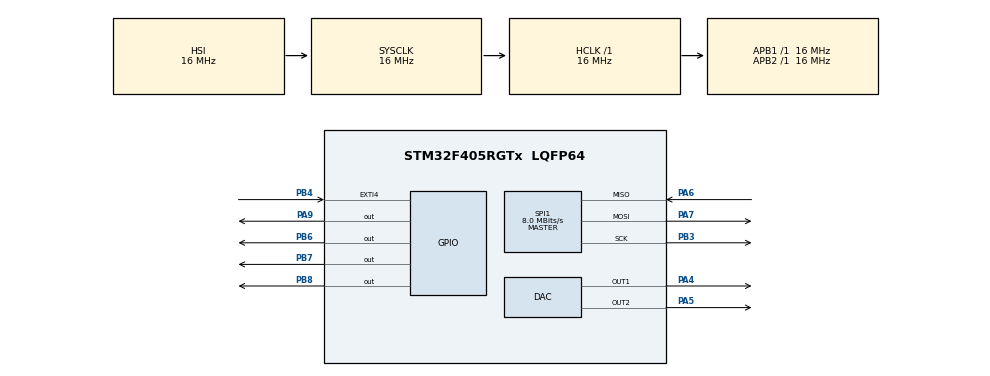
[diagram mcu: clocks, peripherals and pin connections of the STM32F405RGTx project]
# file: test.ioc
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Dma.Request0=SPI1_TX
Dma.SPI1_TX.0.Direction=DMA_MEMORY_TO_PERIPH
Dma.SPI1_TX.0.FIFOMode=DMA_FIFOMODE_DISABLE
Dma.SPI1_TX.0.Instance=DMA2_Stream3
Dma.SPI1_TX.0.MemDataAlignment=DMA_MDATAALIGN_BYTE
Dma.SPI1_TX.0.MemInc=DMA_MINC_ENABLE
Dma.SPI1_TX.0.Mode=DMA_NORMAL
Dma.SPI1_TX.0.PeriphDataAlignment=DMA_PDATAALIGN_BYTE
Dma.SPI1_TX.0.PeriphInc=DMA_PINC_DISABLE
Dma.SPI1_TX.0.Priority=DMA_PRIORITY_LOW
Mcu.Family=STM32F4
Mcu.Name=STM32F405RGTx
Mcu.Package=LQFP64
NVIC.DMA2_Stream3_IRQn=true\:0\:0\:false\:false\:true\:false\:true\:true
NVIC.EXTI4_IRQn=true\:0\:0\:false\:false\:true\:true\:true\:true
NVIC.PriorityGroup=NVIC_PRIORITYGROUP_4
PA13.Mode=Serial_Wire
PA13.Signal=SYS_JTMS-SWDIO
PA14.Mode=Serial_Wire
PA14.Signal=SYS_JTCK-SWCLK
PA4.Signal=COMP_DAC1_group
PA5.Signal=COMP_DAC2_group
PA6.GPIO_PuPd=GPIO_PULLUP
PA6.Mode=Full_Duplex_Master
PA6.Signal=SPI1_MISO
PA7.GPIO_PuPd=GPIO_PULLUP
PA7.Mode=Full_Duplex_Master
PA7.Signal=SPI1_MOSI
PA9.Signal=GPIO_Output
PB3.GPIO_PuPd=GPIO_PULLUP
PB3.Mode=Full_Duplex_Master
PB3.Signal=SPI1_SCK
PB4.Signal=GPXTI4
PB6.PinState=GPIO_PIN_SET
PB6.Signal=GPIO_Output
PB7.Signal=GPIO_Output
PB8.Signal=GPIO_Output
PH0-OSC_IN.Mode=HSE-External-Oscillator
PH0-OSC_IN.Signal=RCC_OSC_IN
PH1-OSC_OUT.Mode=HSE-External-Oscillator
PH1-OSC_OUT.Signal=RCC_OSC_OUT
ProjectManager.HeapSize=0x200
ProjectManager.StackSize=0x400
ProjectManager.TargetToolchain=STM32CubeIDE
RCC.AHBFreq_Value=16000000
RCC.APB1Freq_Value=16000000
RCC.APB2Freq_Value=16000000
RCC.CortexFreq_Value=16000000
RCC.HSE_VALUE=25000000
RCC.HSI_VALUE=16000000
RCC.LSE_VALUE=32768
RCC.SYSCLKFreq_VALUE=16000000
RCC.VCOOutputFreq_Value=192000000
SH.COMP_DAC1_group.0=DAC_OUT1,DAC_OUT1
SH.COMP_DAC2_group.0=DAC_OUT2,DAC_OUT2
SPI1.CalculateBaudRate=8.0 MBits/s
SPI1.Direction=SPI_DIRECTION_2LINES
SPI1.Mode=SPI_MODE_MASTER
SPI1.VirtualType=VM_MASTER
board=custom

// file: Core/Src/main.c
/* USER CODE BEGIN Header */
/**
  ******************************************************************************
  * @file           : main.c
  * @brief          : Main program body
  ******************************************************************************
  * @attention
  *
  * Copyright (c) 2024 STMicroelectronics.
  * All rights reserved.
  *
  * This software is licensed under terms that can be found in the LICENSE file
  * in the root directory of this software component.
  * If no LICENSE file comes with this software, it is provided AS-IS.
  *
  ******************************************************************************
  */
/* USER CODE END Header */
#include "main.h"

/* USER CODE BEGIN Includes */
#include "st7789.h"
/* USER CODE END Includes */

DAC_HandleTypeDef hdac;

SPI_HandleTypeDef hspi1;
DMA_HandleTypeDef hdma_spi1_tx;

void SystemClock_Config(void);
static void MX_GPIO_Init(void);
static void MX_DMA_Init(void);
static void MX_DAC_Init(void);
static void MX_SPI1_Init(void);

int main(void)
{

  /* MCU Configuration--------------------------------------------------------*/

  /* Reset of all peripherals, Initializes the Flash interface and the Systick. */
  HAL_Init();

  /* Configure the system clock */
  SystemClock_Config();

  /* Initialize all configured peripherals */
  MX_GPIO_Init();
  MX_DMA_Init();
  MX_DAC_Init();
  MX_SPI1_Init();
  /* USER CODE BEGIN 2 */
  ST7789_Init();
//  ST7789_Test();
  ST7789_WriteString(10, 10, "Hello Nguyen Dang Tri", Font_7x10, RED, BLACK);
  /* USER CODE END 2 */

  /* Infinite loop */
  while (1)
  {

  }
}

void SystemClock_Config(void)
{
  RCC_OscInitTypeDef RCC_OscInitStruct = {0};
  RCC_ClkInitTypeDef RCC_ClkInitStruct = {0};

  /** Configure the main internal regulator output voltage
  */
  __HAL_RCC_PWR_CLK_ENABLE();
  __HAL_PWR_VOLTAGESCALING_CONFIG(PWR_REGULATOR_VOLTAGE_SCALE1);

  /** Initializes the RCC Oscillators according to the specified parameters
  * in the RCC_OscInitTypeDef structure.
  */
  RCC_OscInitStruct.OscillatorType = RCC_OSCILLATORTYPE_HSI;
  RCC_OscInitStruct.HSIState = RCC_HSI_ON;
  RCC_OscInitStruct.HSICalibrationValue = RCC_HSICALIBRATION_DEFAULT;
  RCC_OscInitStruct.PLL.PLLState = RCC_PLL_NONE;
  if (HAL_RCC_OscConfig(&RCC_OscInitStruct) != HAL_OK)
  {
    Error_Handler();
  }

  /** Initializes the CPU, AHB and APB buses clocks
  */
  RCC_ClkInitStruct.ClockType = RCC_CLOCKTYPE_HCLK|RCC_CLOCKTYPE_SYSCLK
                              |RCC_CLOCKTYPE_PCLK1|RCC_CLOCKTYPE_PCLK2;
  RCC_ClkInitStruct.SYSCLKSource = RCC_SYSCLKSOURCE_HSI;
  RCC_ClkInitStruct.AHBCLKDivider = RCC_SYSCLK_DIV1;
  RCC_ClkInitStruct.APB1CLKDivider = RCC_HCLK_DIV1;
  RCC_ClkInitStruct.APB2CLKDivider = RCC_HCLK_DIV1;

  if (HAL_RCC_ClockConfig(&RCC_ClkInitStruct, FLASH_LATENCY_0) != HAL_OK)
  {
    Error_Handler();
  }
}

static void MX_DAC_Init(void)
{

  DAC_ChannelConfTypeDef sConfig = {0};

  /** DAC Initialization
  */
  hdac.Instance = DAC;
  if (HAL_DAC_Init(&hdac) != HAL_OK)
  {
    Error_Handler();
  }

  /** DAC channel OUT1 config
  */
  sConfig.DAC_Trigger = DAC_TRIGGER_NONE;
  sConfig.DAC_OutputBuffer = DAC_OUTPUTBUFFER_ENABLE;
  if (HAL_DAC_ConfigChannel(&hdac, &sConfig, DAC_CHANNEL_1) != HAL_OK)
  {
    Error_Handler();
  }

  /** DAC channel OUT2 config
  */
  if (HAL_DAC_ConfigChannel(&hdac, &sConfig, DAC_CHANNEL_2) != HAL_OK)
  {
    Error_Handler();
  }

}

static void MX_SPI1_Init(void)
{

  /* SPI1 parameter configuration*/
  hspi1.Instance = SPI1;
  hspi1.Init.Mode = SPI_MODE_MASTER;
  hspi1.Init.Direction = SPI_DIRECTION_2LINES;
  hspi1.Init.DataSize = SPI_DATASIZE_8BIT;
  hspi1.Init.CLKPolarity = SPI_POLARITY_LOW;
  hspi1.Init.CLKPhase = SPI_PHASE_1EDGE;
  hspi1.Init.NSS = SPI_NSS_SOFT;
  hspi1.Init.BaudRatePrescaler = SPI_BAUDRATEPRESCALER_2;
  hspi1.Init.FirstBit = SPI_FIRSTBIT_MSB;
  hspi1.Init.TIMode = SPI_TIMODE_DISABLE;
  hspi1.Init.CRCCalculation = SPI_CRCCALCULATION_DISABLE;
  hspi1.Init.CRCPolynomial = 10;
  if (HAL_SPI_Init(&hspi1) != HAL_OK)
  {
    Error_Handler();
  }

}

static void MX_DMA_Init(void)
{

  /* DMA controller clock enable */
  __HAL_RCC_DMA2_CLK_ENABLE();

  /* DMA interrupt init */
  /* DMA2_Stream3_IRQn interrupt configuration */
  HAL_NVIC_SetPriority(DMA2_Stream3_IRQn, 0, 0);
  HAL_NVIC_EnableIRQ(DMA2_Stream3_IRQn);

}

static void MX_GPIO_Init(void)
{
  GPIO_InitTypeDef GPIO_InitStruct = {0};

  /* GPIO Ports Clock Enable */
  __HAL_RCC_GPIOH_CLK_ENABLE();
  __HAL_RCC_GPIOA_CLK_ENABLE();
  __HAL_RCC_GPIOB_CLK_ENABLE();

  /*Configure GPIO pin Output Level */
  HAL_GPIO_WritePin(GPIOA, GPIO_PIN_9, GPIO_PIN_RESET);

  /*Configure GPIO pin Output Level */
  HAL_GPIO_WritePin(GPIOB, GPIO_PIN_6, GPIO_PIN_SET);

  /*Configure GPIO pin Output Level */
  HAL_GPIO_WritePin(GPIOB, GPIO_PIN_7|GPIO_PIN_8, GPIO_PIN_RESET);

  /*Configure GPIO pin : PA9 */
  GPIO_InitStruct.Pin = GPIO_PIN_9;
  GPIO_InitStruct.Mode = GPIO_MODE_OUTPUT_PP;
  GPIO_InitStruct.Pull = GPIO_NOPULL;
  GPIO_InitStruct.Speed = GPIO_SPEED_FREQ_LOW;
  HAL_GPIO_Init(GPIOA, &GPIO_InitStruct);

  /*Configure GPIO pin : PB4 */
  GPIO_InitStruct.Pin = GPIO_PIN_4;
  GPIO_InitStruct.Mode = GPIO_MODE_IT_RISING;
  GPIO_InitStruct.Pull = GPIO_NOPULL;
  HAL_GPIO_Init(GPIOB, &GPIO_InitStruct);

  /*Configure GPIO pins : PB6 PB7 PB8 */
  GPIO_InitStruct.Pin = GPIO_PIN_6|GPIO_PIN_7|GPIO_PIN_8;
  GPIO_InitStruct.Mode = GPIO_MODE_OUTPUT_PP;
  GPIO_InitStruct.Pull = GPIO_NOPULL;
  GPIO_InitStruct.Speed = GPIO_SPEED_FREQ_LOW;
  HAL_GPIO_Init(GPIOB, &GPIO_InitStruct);

  /* EXTI interrupt init*/
  HAL_NVIC_SetPriority(EXTI4_IRQn, 0, 0);
  HAL_NVIC_EnableIRQ(EXTI4_IRQn);

}

void Error_Handler(void)
{
  __disable_irq();
  while (1)
  {
  }
}
